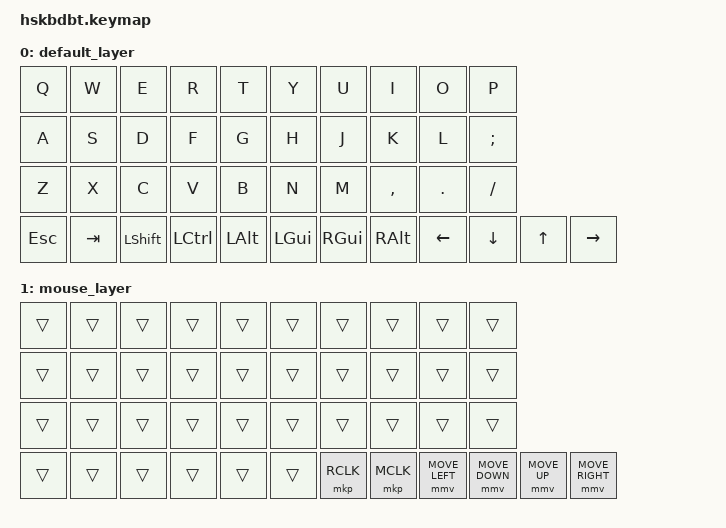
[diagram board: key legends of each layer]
// This file was generated from a template. Edit it to match your keyboard.
// See https://zmk.dev/docs/development/hardware-integration/new-shield for more instructions.

#include <behaviors.dtsi>
#include <dt-bindings/zmk/keys.h>
#include <dt-bindings/zmk/mouse.h>

/ {
    // Define a default keymap here.
    // See https://zmk.dev/docs/development/hardware-integration/new-shield#default-keymap.
    keymap {
        compatible = "zmk,keymap";

        // Sensor order follows `sensors = <&left_encoder &right_encoder>` in dtsi.
        sensor-bindings = <
            &inc_dec_kp C_VOL_UP C_VOL_DN
            &inc_dec_kp PG_UP PG_DN
        >;

        default_layer {
            bindings = <
                &kp Q    &kp W    &kp E    &kp R    &kp T           &kp Y    &kp U     &kp I    &kp O     &kp P
                &kp A    &kp S    &kp D    &kp F    &kp G           &kp H    &kp J     &kp K    &kp L     &kp SEMI
                &kp Z    &kp X    &kp C    &kp V    &kp B           &kp N    &kp M     &kp COMMA &kp DOT  &kp FSLH
                &kp ESC  &kp TAB  &kp LSHFT &kp LCTRL &kp LALT  &kp LGUI &kp RGUI  &kp RALT &kp LEFT  &kp DOWN  &kp UP  &kp RIGHT
            >;

            sensor-bindings =
                <&inc_dec_kp C_VOL_UP C_VOL_DN>,
                <&inc_dec_kp PG_UP PG_DN>;
        };

        mouse_layer {
            bindings = <
                &trans   &trans   &trans   &trans   &trans          &trans   &trans   &trans   &trans    &trans
                &trans   &trans   &trans   &trans   &trans          &trans   &trans   &trans   &trans    &trans
                &trans   &trans   &trans   &trans   &trans          &trans   &trans   &trans   &trans    &trans
                &trans   &trans   &trans   &trans   &trans          &trans   &mkp RCLK &mkp MCLK &mmv MOVE_LEFT 1500 &mmv MOVE_DOWN 1500 &mmv MOVE_UP 1500 &mmv MOVE_RIGHT 1500
            >;
        };
    };
};

